# SAMA7D65D2GN8 register map
Vendor: Microchip Technology; Series: SAMA7D6; File version: 0
Registers are 32-bit, read-write, reset 0x0 unless marked. A register's access mark holds for its fields unless they carry their own. Offsets are from the block's base; [hi:lo] are bit positions; {n}, {i} and the like mark numbered series; 'fields as' and 'values as' point back to an identical list.

## I3CC — I3C Host Controller
Base 0xE9000000
0x00 HCI_VERSION ro reset 0x100
  [31:0] VERSION — HCI Version
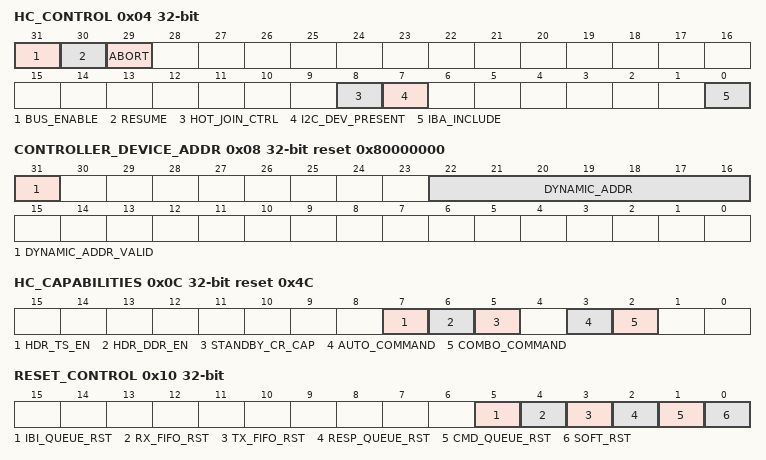
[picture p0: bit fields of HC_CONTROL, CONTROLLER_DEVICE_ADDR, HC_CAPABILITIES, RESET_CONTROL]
0x04 HC_CONTROL — Controller Control Register
  [31] BUS_ENABLE — I3CC Bus Enable
    0=Disables I3CC bus operations when writing a '0' or indicates the I3CC operations are completed when reading '0'; 1=Enables I3CC bus operations
  [30] RESUME — I3CC Resume
    0=(RUNNING) The I3CC running; 1=(SUSPENDED) The I3CC is suspended
  [29] ABORT — I3CC Abort
    0=The driver clears the ABORT bit to allow operation on the bus; 1=The I3CC aborts a transfer by issuing the STOP condition on the I3C Bus after the complete data byte is transferred or received
  [8] HOT_JOIN_CTRL — Hot-Join ACK/NACK Control
    1=NACK and send broadcast CCC to disable Hot-Join
  [7] I2C_DEV_PRESENT — I2C Device Present on Bus
    0=Legacy I2C devices must not be present on the I3C bus; 1=Legacy I2C devices can be present on the I3C bus
  [0] IBA_INCLUDE — Include I3C Broadcast Address
    0=Do not include I3C Broadcast Address for private transfers; 1=Include I3C Broadcast Address for private transfers
0x08 CONTROLLER_DEVICE_ADDR reset 0x80000000 — Controller Device Address Register
  [31] DYNAMIC_ADDR_VALID — Device Dynamic Address Valid
    0=Invalidates DYNAMIC_ADDR; 1=Validates DYNAMIC_ADDR
  [22:16] DYNAMIC_ADDR — Device Dynamic Address
0x0C HC_CAPABILITIES ro reset 0x4C — Controller Capabilities Register
  [7] HDR_TS_EN — HDR Ternary Symbol Transfer
    0=HDR-TS not supported; 1=HDR-TS supported
  [6] HDR_DDR_EN — HDR-DDR transfers
    0=HDR-DDR not supported; 1=HDR-DDR supported
  [5] STANDBY_CR_CAP — Standby I3CC Capability
    0=Not capable of acting as standby controller; 1=Capable acting as standby controller (i.e., secondary controller)
  [3] AUTO_COMMAND
    0=IBI Auto Command transfers is not supported; 1=IBI Auto Command transfers is supported
  [2] COMBO_COMMAND — Combo Command Transfers
    0=Combo Command transfers not supported; 1=Combo Command transfers supported
0x10 RESET_CONTROL
  [5] IBI_QUEUE_RST — IBI Queue Reset
    0=No effect; 1=The IBI queues in the I3CC are flushed. Cleared automatically upon IBI queue reset completion.
  [4] RX_FIFO_RST — Receive Queue Software Reset
    0=No effect; 1=The Receive queues in the I3CC are flushed. Cleared automatically upon Receive queue reset completion.
  [3] TX_FIFO_RST — Transmit Queue Software Reset
    0=No effect; 1=The Transmit queues in the I3CC are flushed. Cleared automatically upon Transmit queue reset completion.
  [2] RESP_QUEUE_RST — Response Queue Software Reset
    0=No effect; 1=The Response queues in the I3CC are flushed. Cleared automatically upon Response queue reset completion.
  [1] CMD_QUEUE_RST — Command Queue Software reset
    0=No effect; 1=The Command queues in the I3CC are flushed. Cleared automatically upon Command queue reset completion.
  [0] SOFT_RST — Core Software Reset
    0=No effect; 1=The I3CC is reset and disabled. All registers return to their reset values, and the software must re-initialize the I3CC.
0x14 PRESENT_STATE ro
  [2] CURRENT_CONTROLLER — Active Controller
    1=(BUS_OWNER) The I3CC is the active controller and, as a result, can initiate transfers
0x20 INTR_STATUS — Interrupt Status Register
  [10] HC_INTERNAL_ERR_STAT — I3CC Internal Error
0x24 INTR_STATUS_ENABLE — Interrupt Status Enable Register
  [10] HC_INTERNAL_ERR_STAT_EN — I3CC Internal Error Status Enable
    0=Disables the HC_INTERNAL_ERR_STAT interrupt bit logging; 1=Enables the HC_INTERNAL_ERR_STAT interrupt bit logging
0x28 INTR_SIGNAL_ENABLE — Interrupt Signal Enable Register
  [10] HC_INTERNAL_ERR_SIGNAL_EN — I3CC Internal Error Signal Enable
    0=The I3CC interrupt line is not triggered by I3CC_INTR_STATUS.HC_INTERNAL_ERR_STAT; 1=If I3CC_INTR_STATUS.HC_INTERNAL_ERR_STAT is set to '1', the I3CC interrupt line is triggered
0x2C INTR_FORCE wo — Interrupt Force Register
  [10] INTR_FORCE — I3CC Internal Error Force
    0=No effect; 1=Sets I3CC_INTR_STATUS.HC_INTERNAL_ERR_STAT interrupt source to '1'
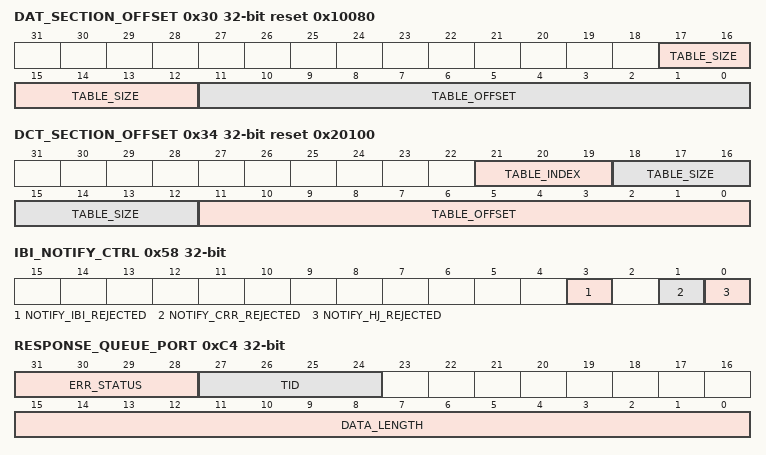
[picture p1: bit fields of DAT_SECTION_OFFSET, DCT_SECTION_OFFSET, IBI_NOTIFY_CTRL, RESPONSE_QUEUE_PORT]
0x30 DAT_SECTION_OFFSET ro reset 0x10080 — Device Address Table Section Offset Register
  [17:12] TABLE_SIZE — DAT Table Size
  [11:0] TABLE_OFFSET — DAT Table Offset
0x34 DCT_SECTION_OFFSET reset 0x20100 — Device Characteristics Table Section Offset Register
  [21:19] TABLE_INDEX — DCT Table Index
  [18:12] TABLE_SIZE — DCT Table Size
  [11:0] TABLE_OFFSET — DCT Table Offset
0x38 RING_HEADERS_SECTION_OFFSET ro
  [15:0] SECTION_OFFSET — Ring Headers Section Offset
0x3C PIO_SECTION_OFFSET ro reset 0xC0
  [15:0] SECTION_OFFSET — PIO Section Offset
0x40 EXT_CAPS_SECTION_OFFSET ro reset 0x200 — Extended Capabilities Section Offset Register
  [15:0] SECTION_OFFSET — Extended Capabilities Section Offset
0x58 IBI_NOTIFY_CTRL — IBI Notify Control Register
  [3] NOTIFY_IBI_REJECTED — Notify Rejected In-Band Interrupt Request Control
    0=(DISABLED) Do not pass rejected IBI status to the IBI queue/rings, if the incoming IBI is NACK'ed and is auto-disabled based on the IBI_REJECT field in relevant DAT entry; 1=(ENABLED) Pass rejected IBI status to the IBI queue/rings, if the incoming IBI is NACK'ed and is auto-disabled based on the IBI_REJECT field in the relevant DAT entry
  [1] NOTIFY_CRR_REJECTED — Notify Rejected Controller-role Request Control
    0=(DISABLED) Do not pass rejected IBI status to IBI queue/ring, if the incoming controller-role request is NACK'ed and is auto-disabled based on the CRR_REJECT field in the relevant DAT entry; 1=(ENABLED) Pass rejected IBI status to the IBI queue, if the incoming controller-role request is NACK'ed and is auto-disabled based on the CRR_REJECT field in the relevant DAT entry
  [0] NOTIFY_HJ_REJECTED — Notify Rejected Hot-Join Control
    0=(DISABLED) Do not pass rejected IBI status to IBI queue, if the incoming hot-join request is NACK'ed and is auto-disabled based on I3CC_HC_CONTROL.HOT_JOIN_CTRL; 1=(ENABLED) Pass rejected IBI status to the IBI queue, if the incoming hot join request is NACK'ed and is auto-disabled based on I3CC_HC_CONTROL.HOT_JOIN_CTRL
0x60 DEV_CTX_BASE_LO ro — Device Context Base Address Low Register
  [31:0] BASE_LO — Device Context Base Low
0x64 DEV_CTX_BASE_HI ro — Device Context Base Address High Register
  [31:0] BASE_HI — Device Context Base High
0xC0 COMMAND_QUEUE_PORT wo
  [31:0] COMMAND — 32-bit Command Part
0xC4 RESPONSE_QUEUE_PORT ro
  [31:28] ERR_STATUS — Response Error Status
    0=SUCCESS (Transfer successful, no error); 1=CRC (CRC error); 2=PARITY (Parity error); 3=FRAME (Frame error); 4=ADDR_HEADER (Address header error); 5=NACK (Address NACK'ed or Dynamic Address Assignment NACK'ed); 6=OVL (Receive overflow or transfer underflow error); 8=ABORTED
  [27:24] TID — Command/Response Transaction ID
  [15:0] DATA_LENGTH — Data Length/Device Count
0xC8 XFER_DATA_PORT — Transfer Data Port Register
  [31:0] DATA — 32-bit Data
0xCC IBI_PORT ro
  [31:0] IBI_DATA — Data Read from IBI Data Buffer
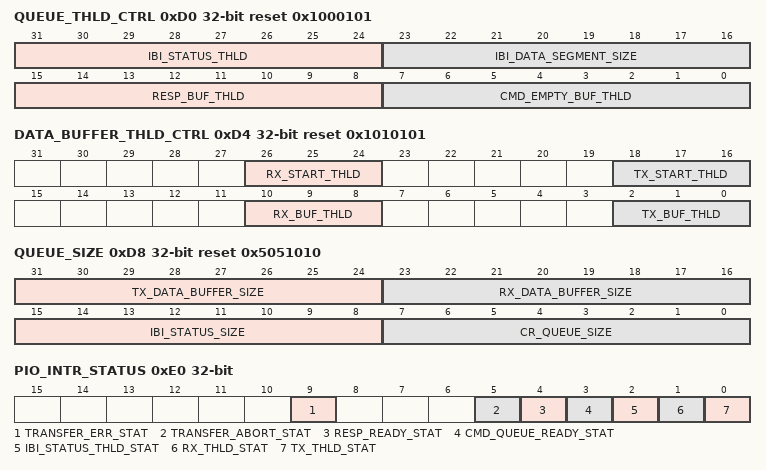
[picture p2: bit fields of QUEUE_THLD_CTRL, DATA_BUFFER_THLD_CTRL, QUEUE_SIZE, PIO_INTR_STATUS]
0xD0 QUEUE_THLD_CTRL reset 0x1000101 — Queue Threshold Control Register
  [31:24] IBI_STATUS_THLD — IBI Status Threshold
    0=Interrupt is triggered when the outstanding IBI status count in the IBI queue reaches 1 or above
  [23:16] IBI_DATA_SEGMENT_SIZE
  [15:8] RESP_BUF_THLD — Response Ready Buffer Threshold
    0=Interrupt is triggered when response queue contains 1 entry (32-bit word)
  [7:0] CMD_EMPTY_BUF_THLD — Command Ready Buffer Threshold
    0=Interrupt is issued when command queue is completely empty
0xD4 DATA_BUFFER_THLD_CTRL reset 0x1010101 — Transfer Data Buffer Threshold Control Register
  [26:24] RX_START_THLD — Receive Start Threshold
    0=1_ENTRY (1 available FIFO entry); 1=4_ENTRIES (4 available FIFO entries); 2=8_ENTRIES (8 available FIFO entries); 3=16_ENTRIES (16 available FIFO entries); 4=32_ENTRIES (32 available FIFO entries); 5=64_ENTRIES (64 available FIFO entries)
  [18:16] TX_START_THLD — Transmit (Transfer) Start Threshold
    0=1_WORD (1 available transmit data); 1=4_WORDS (4 available transmit data); 2=8_WORDS (8 available transmit data); 3=16_WORDS (16 available transmit data); 4=32_WORDS (32 available transmit data); 5=64_WORDS (64 available transmit data)
  [10:8] RX_BUF_THLD — Receive Buffer Threshold
    0=1_WORD (1 received data); 1=4_WORDS (4 received data); 2=8_WORDS (8 received data); 3=16_WORDS (16 received data); 4=32_WORDS (32 received data); 5=64_WORDS (64 received data)
  [2:0] TX_BUF_THLD — Transmit Buffer Threshold
    values as RX_START_THLD
0xD8 QUEUE_SIZE ro reset 0x5051010
  [31:24] TX_DATA_BUFFER_SIZE — Transmit Data Buffer Size
    0=2_WORDS (2 32-bit words); 1=4_WORDS (4 32-bit words); 2=8_WORDS (8 32-bit words); 3=16_WORDS (16 32-bit words); 4=32_WORDS (32 32-bit words); 5=64_WORDS (64 32-bit words); 6=128_WORDS (128 32-bit words); 7=256_WORDS (256 32-bit words)
  [23:16] RX_DATA_BUFFER_SIZE — Receive Data Buffer Size
    values as TX_DATA_BUFFER_SIZE
  [15:8] IBI_STATUS_SIZE — IBI Queue Size
  [7:0] CR_QUEUE_SIZE — Command/Response Queue Size
0xE0 PIO_INTR_STATUS — PIO Interrupt Status Register
  [9] TRANSFER_ERR_STAT — Transfer Error Status
  [5] TRANSFER_ABORT_STAT — Transfer Abort Status
  [4] RESP_READY_STAT — Response Ready Status
  [3] CMD_QUEUE_READY_STAT — Command Queue Ready Status
  [2] IBI_STATUS_THLD_STAT — IBI Status Threshold Status
  [1] RX_THLD_STAT — Receive Data Buffer Threshold Status
  [0] TX_THLD_STAT — Transmit Data Buffer Threshold Status
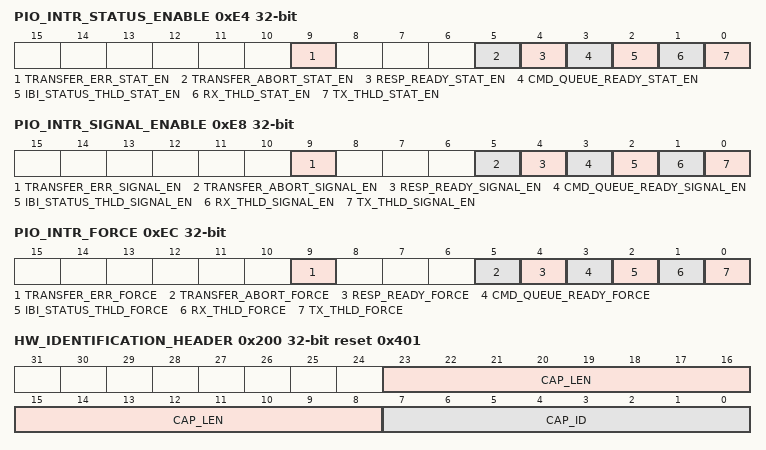
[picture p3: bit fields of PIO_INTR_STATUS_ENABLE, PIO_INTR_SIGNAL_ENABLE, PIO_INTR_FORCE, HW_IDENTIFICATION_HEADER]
0xE4 PIO_INTR_STATUS_ENABLE — PIO Interrupt Status Enable Register
  [9] TRANSFER_ERR_STAT_EN — Transfer Error Status Enable
    0=Disables interrupt status logging for TRANSFER_ERR_STAT; 1=Enables interrupt status logging for TRANSFER_ERR_STAT
  [5] TRANSFER_ABORT_STAT_EN — Transfer Abort Status Enable
    0=Disables interrupt status logging for TRANSFER_ABORT_STAT; 1=Enables interrupt status logging for TRANSFER_ABORT_STAT
  [4] RESP_READY_STAT_EN — Response Ready Status Enable
    0=Disables interrupt status logging for RESP_READY_STAT; 1=Enables interrupt status logging for RESP_READY_STAT
  [3] CMD_QUEUE_READY_STAT_EN — Command Queue Ready Status Enable
    0=Disables interrupt status logging for CMD_QUEUE_READY_STAT; 1=Enables interrupt status logging for CMD_QUEUE_READY_STAT
  [2] IBI_STATUS_THLD_STAT_EN — IBI Status Threshold Status Enable
    0=Disables interrupt status logging for IBI_STATUS_THLD_STAT; 1=Enables interrupt status logging for IBI_STATUS_THLD_STAT
  [1] RX_THLD_STAT_EN — Receive Data Buffer Threshold Status Enable
    0=Disables interrupt status logging for RX_THLD_STAT; 1=Enables interrupt status logging for RX_THLD_STAT
  [0] TX_THLD_STAT_EN — Transmit Data Buffer Threshold Status Enable
    0=Disables interrupt status logging for TX_THLD_STAT; 1=Enables interrupt status logging for TX_THLD_STAT
0xE8 PIO_INTR_SIGNAL_ENABLE — PIO Interrupt Signal Enable Register
  [9] TRANSFER_ERR_SIGNAL_EN — Transfer Error Signal Enable
    0=TRANSFER_ERR_STAT cannot trigger the interrupt line; 1=TRANSFER_ERR_STAT triggers the interrupt line
  [5] TRANSFER_ABORT_SIGNAL_EN — Transfer Abort Signal Enable
    0=TRANSFER_ABORT_STAT cannot trigger the interrupt line; 1=TRANSFER_ABORT_STAT triggers the interrupt line
  [4] RESP_READY_SIGNAL_EN — Response Ready Signal Enable
    0=RESP_READY_STAT cannot trigger the interrupt line; 1=RESP_READY_STAT triggers the interrupt line
  [3] CMD_QUEUE_READY_SIGNAL_EN — Command Queue Ready Signal Enable
    0=CMD_QUEUE_READY_STAT cannot trigger the interrupt line; 1=CMD_QUEUE_READY_STAT triggers the interrupt line
  [2] IBI_STATUS_THLD_SIGNAL_EN — IBI Status Threshold Signal Enable
    0=IBI_STATUS_THLD_STAT cannot trigger the interrupt line; 1=IBI_STATUS_THLD_STAT triggers the interrupt line
  [1] RX_THLD_SIGNAL_EN — Receive Data Buffer Threshold Signal Enable
    0=RX_THLD_STAT cannot trigger the interrupt line; 1=RX_THLD_STAT triggers the interrupt line
  [0] TX_THLD_SIGNAL_EN — Transmit Data Buffer Threshold Signal Enable
    0=TX_THLD_STAT cannot trigger the interrupt line; 1=TX_THLD_STAT triggers the interrupt line
0xEC PIO_INTR_FORCE wo — PIO Interrupt Force Register
  [9] TRANSFER_ERR_FORCE — Transfer Error Status Force
    0=No effect; 1=Sets TRANSFER_ERR_STAT to 1
  [5] TRANSFER_ABORT_FORCE — Transfer Abort Status Force
    0=No effect; 1=Sets TRANSFER_ABORT_STAT to 1
  [4] RESP_READY_FORCE — Response Ready Status Force
    0=No effect; 1=Sets RESP_READY_STAT to 1
  [3] CMD_QUEUE_READY_FORCE — Command Queue Ready Status Force
    0=No effect; 1=Sets CMD_QUEUE_READY_STAT to 1
  [2] IBI_STATUS_THLD_FORCE — IBI Status Threshold Status Force
    0=No effect; 1=Sets IBI_STATUS_THLD_STAT to 1
  [1] RX_THLD_FORCE — Receive Data Buffer Threshold Status Force
    0=No effect; 1=Sets RX_THLD_STAT to 1
  [0] TX_THLD_FORCE — Transmit Data Buffer Threshold Status Force
    0=No effect; 1=Sets TX_THLD_STAT to 1
0x200 HW_IDENTIFICATION_HEADER ro reset 0x401 — Hardware Identification Header Register
  [23:8] CAP_LEN — Capability Structure Length
  [7:0] CAP_ID — Extended Capability ID
0x204 COMP_MANUFACTURER ro — Component Manufacturer Register
  [31:0] MIPI_VENDOR_ID
0x208 COMP_VERSION ro reset 0x3130312A — Component Version Register
  [31:0] I3C_VER_ID — I3CC Component Version
0x20C COMP_TYPE ro reset 0x65613030 — Component Type Register
  [31:0] I3C_PRODUCT_ID — I3CC Component Type
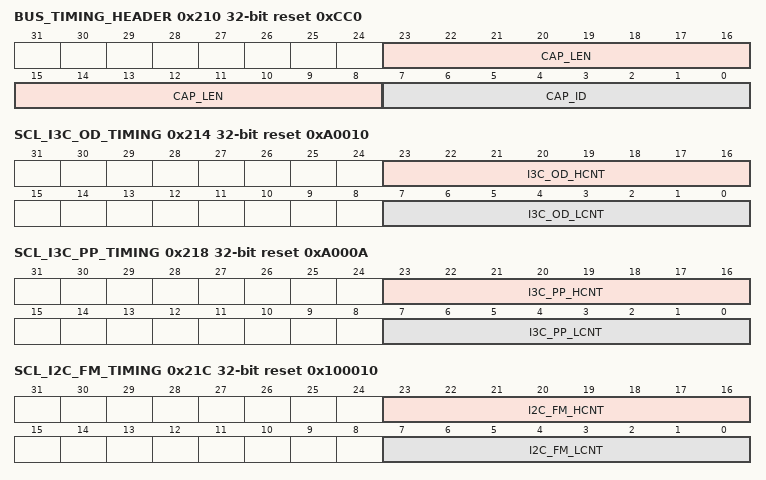
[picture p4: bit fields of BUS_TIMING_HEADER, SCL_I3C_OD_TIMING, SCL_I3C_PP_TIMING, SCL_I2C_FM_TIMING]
0x210 BUS_TIMING_HEADER ro reset 0xCC0
  fields as HW_IDENTIFICATION_HEADER
0x214 SCL_I3C_OD_TIMING reset 0xA0010 — SCL I3C Open-Drain Timing Register
  [23:16] I3C_OD_HCNT — I3C Open-Drain High Count
  [7:0] I3C_OD_LCNT — I3C Open-Drain Low Count
0x218 SCL_I3C_PP_TIMING reset 0xA000A — SCL I3C Push-Pull Timing Register
  [23:16] I3C_PP_HCNT — I3C Push-Pull High Count
  [7:0] I3C_PP_LCNT — I3C Push-Pull Low Count
0x21C SCL_I2C_FM_TIMING reset 0x100010 — SCL I2C Fast Mode Timing Register
  [23:16] I2C_FM_HCNT — I2C Fast Mode High Count
  [7:0] I2C_FM_LCNT — I2C Fast Mode Low Count
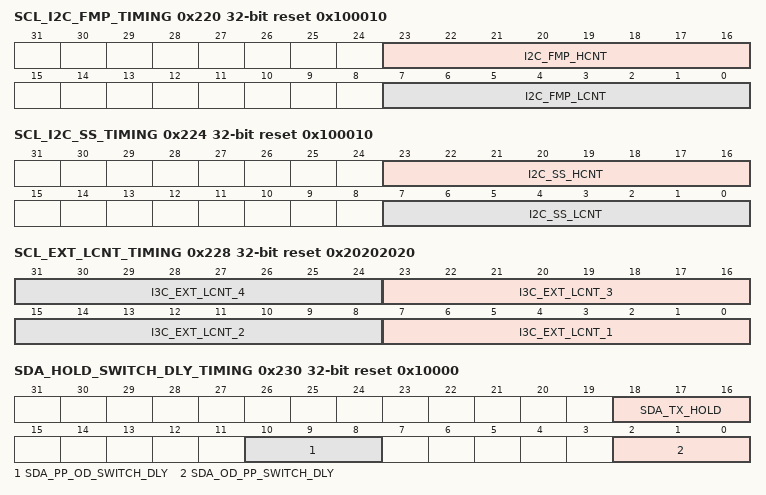
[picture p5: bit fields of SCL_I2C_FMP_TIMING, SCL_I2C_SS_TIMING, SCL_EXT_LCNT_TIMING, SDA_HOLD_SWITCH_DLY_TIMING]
0x220 SCL_I2C_FMP_TIMING reset 0x100010 — SCL I2C Fast Mode Plus Timing Register
  [23:16] I2C_FMP_HCNT — I2C Fast Mode Plus High Count
  [7:0] I2C_FMP_LCNT — I2C Fast Mode Plus Low Count
0x224 SCL_I2C_SS_TIMING reset 0x100010 — SCL I2C Standard Speed Timing Register
  [23:16] I2C_SS_HCNT — I2C Standard Speed High Count
  [7:0] I2C_SS_LCNT — I2C Standard Speed Low Count
0x228 SCL_EXT_LCNT_TIMING reset 0x20202020 — SCL Extended Low Count Timing Register
  [8n-1:8n-8] I3C_EXT_LCNT_{n} (n=1..4) — I3C Extended Low Count Register {n}
0x22C SCL_EXT_TERMN_LCNT_TIMING reset 0x30000 — SCL Termination Bit Low Count Timing Register
  [3:0] I3C_EXT_TERMN_LCNT — I3C Read Termination Bit Low count.
0x230 SDA_HOLD_SWITCH_DLY_TIMING reset 0x10000 — SDA Hold and Mode Switch Delay Timing Register
  [18:16] SDA_TX_HOLD — I3CC_SDA Transmit Hold
  [10:8] SDA_PP_OD_SWITCH_DLY — I3CC_SDA Push-Pull to Open-Drain Switch Delay
  [2:0] SDA_OD_PP_SWITCH_DLY — I3CC_SDA Open-Drain to Push-Pull Switch Delay
0x234 BUS_FREE_TIMING reset 0x20
  [15:0] I3C_HC_FREE — I3C I3CC Free Count
0x23C SCL_LOW_MST_EXT_TIMEOUT reset 0x3567E0 — SCL Low Master Extended Timeout Register
  [25:0] SCL_LOW_MST_TIMEOUT_COUNT — Low Bus Reset Pattern Count
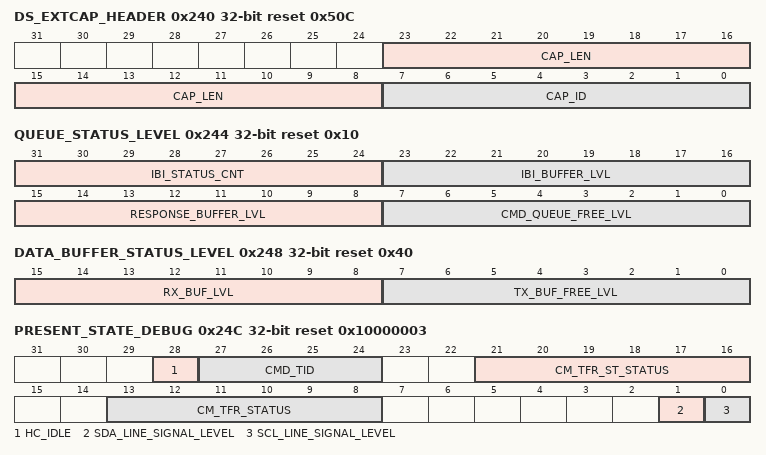
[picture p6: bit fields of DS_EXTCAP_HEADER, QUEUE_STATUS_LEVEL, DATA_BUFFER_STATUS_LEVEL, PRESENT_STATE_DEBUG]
0x240 DS_EXTCAP_HEADER ro reset 0x50C — Debug Specific Header Register
  fields as HW_IDENTIFICATION_HEADER
0x244 QUEUE_STATUS_LEVEL ro reset 0x10
  [31:24] IBI_STATUS_CNT — IBI Buffer Status Count
  [23:16] IBI_BUFFER_LVL — IBI Buffer Level
  [15:8] RESPONSE_BUFFER_LVL — Response Buffer Level
  [7:0] CMD_QUEUE_FREE_LVL — Command Queue Free Buffer Level
0x248 DATA_BUFFER_STATUS_LEVEL ro reset 0x40
  [15:8] RX_BUF_LVL — Receive Data Buffer Status Count
  [7:0] TX_BUF_FREE_LVL — Transmit Data Buffer Status Count
0x24C PRESENT_STATE_DEBUG ro reset 0x10000003
  [28] HC_IDLE — I3CC Idle
    0=(HC_NOT_IDLE) I3CC is not in Idle state; 1=(HC_IDLE) I3CC is in Idle state. All of the queues (Command, Response, IBI) and buffers (Transmit and Receive) are empty.
  [27:24] CMD_TID — Command Transaction ID
  [21:16] CM_TFR_ST_STATUS — I3CC Transfer State Status
    0=IDLE (I3CC is in the Idle state, waiting for commands from the application or for target-initiated IBIs); 1=START (START Generation state); 2=RESTART (RESTART Generation state); 3=STOP (STOP Generation state); 4=START_HOLD (START Hold Generation for the target-initiated START state); 5=BCAST_WRITE (Broadcast Write Address Header(0x7E,W) Generation state); 6=BCAST_READ (Broadcast Read Address Header(0x7E,R) Generation state); 7=DAA (Dynamic Address Assignment state); 8=ADDR (Target Address Generation state); 11=CCC (CCC Byte Generation state); 12=HDR (HDR Command Generation state); 13=WR (Write Data Transfer state); 14=RD (Read Data Transfer state); 15=IBI_ADDR_READ (IBI Address Read Data state); 16=IBI_DIS (IBI Auto-Disable state); 17=HDR_DDR_CRC (HDR-DDR CRC Data Generation/Receive state); 18=CLOCK_EXT (Clock Extension state); 19=HALT (Halt state); 20=IBI_READ (IBI Read Data state)
  [13:8] CM_TFR_STATUS — I3CC Transfer Type Status
    0=IDLE (I3CC is in the Idle state, waiting for commands from the application, or for target-initiated IBIs); 1=BCAST_WRITE (Broadcast CCC Write transfer); 2=TARGET_WRITE (Directed CCC Write transfer); 3=TARGET_READ (Directed CCC Read transfer); 4=ENTDAA (ENTDAA Address Assignment transfer); 5=SETDASA (SETDASA Address Assignment transfer); 6=I3C_SDR_WRITE (Private I3C SDR Write transfer); 7=I3C_SDR_READ (Private I3C SDR Read transfer); 8=I2C_SDR_WRITE (Private I2C SDR Write transfer); 9=I2C_SDR_READ (Private I2C SDR Read transfer); 12=HDR_DDR_WRITE (Private HDR Double-Data Rate (DDR) Write transfer); 13=HDR_DDR_READ (Private HDR Double-Data Rate (DDR) Read transfer); 14=IBI (Servicing IBI transfer); 15=HALTED (I3CC is in the Halt state, waiting for the application to resume through I3CC_HC_CONTROL)
  [1] SDA_LINE_SIGNAL_LEVEL
  [0] SCL_LINE_SIGNAL_LEVEL — I3CC_SCL Line Signal Level
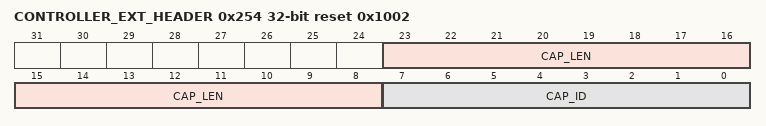
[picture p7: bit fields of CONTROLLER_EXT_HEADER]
0x254 CONTROLLER_EXT_HEADER ro reset 0x1002 — Controller Extended Header Register
  fields as HW_IDENTIFICATION_HEADER
0x258 CONTROLLER_CONFIG ro reset 0x39 — Controller Configuration Register
  [5:4] OPERATION_MODE — Controller Operation Mode
